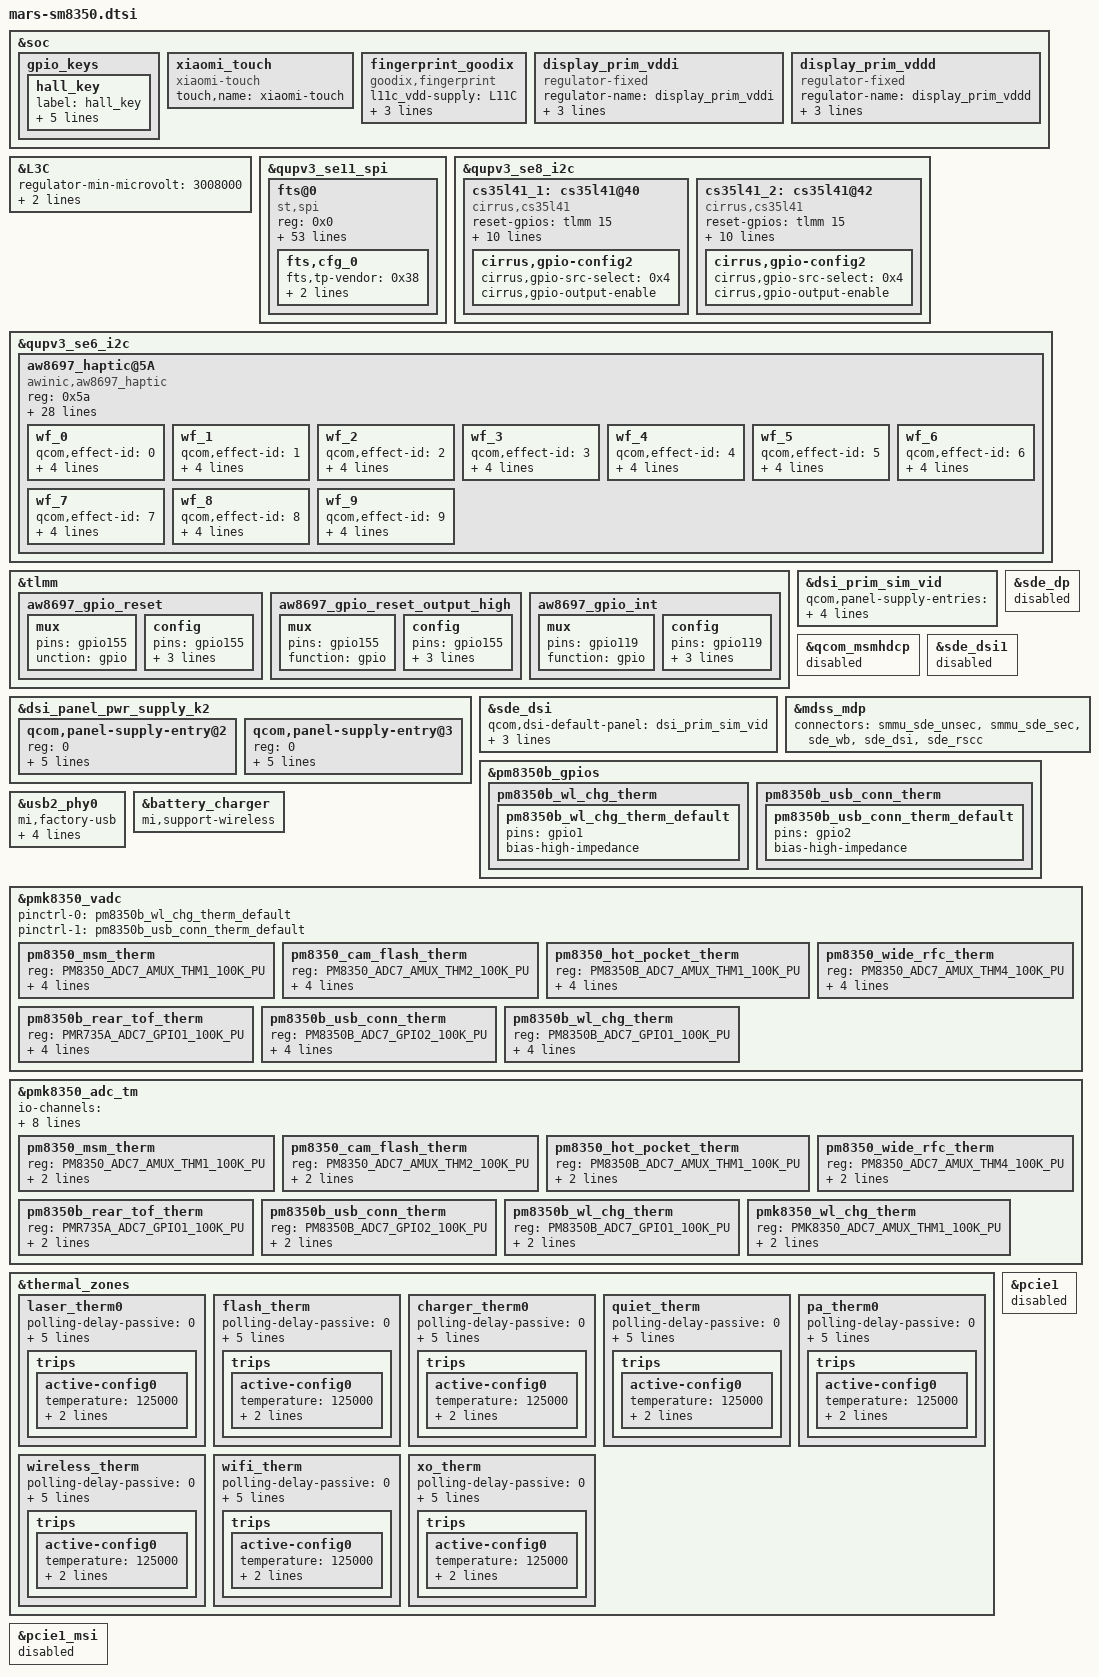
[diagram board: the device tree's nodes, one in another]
/*
this file is for attribution only of mars
And public attribution of xiaomi platforms(like venus and so and)
*/

#include "mars-pinctrl.dtsi"
#include "xiaomi-sm8350-common.dtsi"
#include "mars-audio-overlay.dtsi"
#include "camera/mars-sm8350-camera-sensor.dtsi"

&soc {
	gpio_keys {
		hall_key {
			label = "hall_key";
			gpios = <&tlmm 80 GPIO_ACTIVE_LOW>;
			linux,input-type = <5>;
			linux,code = <0>;
			gpio-key,wakeup;
			debounce-interval = <15>;
		};
	};
	xiaomi_touch {
		compatible = "xiaomi-touch";
		status = "ok";
		touch,name = "xiaomi-touch";
	};

	fingerprint_goodix {
		compatible = "goodix,fingerprint";
		l11c_vdd-supply = <&L11C>;
		goodix,gpio-reset = <&tlmm 39 0x0>;
		goodix,gpio-irq = <&tlmm 38 0x0>;
		fp-gpio-pwr = <&tlmm 13 0x0>;
		status = "ok";
	};

	display_prim_vddi: display_prim_vddi {
		compatible = "regulator-fixed";
		regulator-name = "display_prim_vddi";
		enable-active-high;
		regulator-boot-on;
		gpio = <&tlmm 13 0>;
	};

	display_prim_vddd: display_prim_vddd {
		compatible = "regulator-fixed";
		regulator-name = "display_prim_vddd";
		enable-active-high;
		regulator-boot-on;
		gpio = <&tlmm 74 0>;
	};

};

&L3C {
	regulator-min-microvolt = <3008000>;
	regulator-max-microvolt = <3300000>;
	qcom,init-voltage = <3300000>;
};

&qupv3_se11_spi {
	status = "ok";
	fts@0 {
		status = "ok";
		compatible = "st,spi";
		reg = <0x0>;
		interrupt-parent = <&tlmm>;
		interrupts = <23 0x2008>;
		pinctrl-names = "pmx_ts_active", "pmx_ts_suspend";
		pinctrl-0 = <&mi_ts_active>;
		pinctrl-1 = <&ts_int_suspend &ts_reset_suspend>;
		avdd-supply = <&touch_avddsource_vreg>;
		vdd-supply = <&L2C>;
		fts,pwr-reg-name = "avdd";
		fts,bus-reg-name = "vdd";
		fts,irq-gpio = <&tlmm 23 0x2008>;
		fts,irq-gpio-name = "fts_irq";
		fts,reset-gpio-enable;
		fts,reset-gpio = <&tlmm 22 0x00>;
		fts,reset-gpio-name = "fts_rst";
		fts,irq-flags = <0x2008>;
		fts,x-max = <1440>;
		fts,y-max = <3200>;
		fts,fod-lx = <588>;
		fts,fod-ly = <2358>;
		fts,fod-x-size = <264>;
		fts,fod-y-size = <264>;
		fts,support-fod;
		spi-max-frequency = <7000000>;
		fts,default-fw-name = "st_fts_k2.ftb";
		fts,htp-fw-name = "st_fts_k2_htp.ftb";
		fts,config-array-size = <1>;
		fts,touch-follow-performance-def = <3>;
		fts,touch-tap-sensitivity-def = <4>;
		fts,touch-aim-sensitivity-def = <3>;
		fts,touch-tap-stability-def = <3>;
		fts,cornerfilter-area-step1 = <150>;
		fts,cornerfilter-area-step2 = <280>;
		fts,cornerfilter-area-step3 = <400>;
		fts,touch-deadzone-filter-ver = <2 0 0 0 0 0 0 0
										2 1 0 0 0 0 0 0
										2 2 0 0 0 3199 0 0
										2 3 1439 0 1439 3199 0 0>;
		fts,touch-deadzone-filter-hor = <2 0 0 0 1439 7 0 0
										2 1 0 3192 1439 3199 0 0
										2 2 0 0 0 3199 0 0
										2 3 1439 0 1439 3199 0 0>;
		fts,touch-edgezone-filter-ver = <1 0 0 0 0 0 0 0
										1 1 0 0 0 0 0 0
										1 2 0 0 60 3199 0 0
										1 3 1379 0 1439 3199 0 0>;
		fts,touch-edgezone-filter-hor = <1 0 0 0 1439 70 0 0
										1 1 0 3129 1439 3199 0 0
										1 2 0 0 60 3199 0 0
										1 3 1379 0 1439 3199 0 0>;
		fts,touch-cornerzone-filter-ver = <0 0 0 0 0 0 0 0
										0 1 0 0 0 0 0 0
										0 2 0 2799 250 3199 0 0
										0 3 1189 2799 1439 3199 0 0>;
		fts,touch-cornerzone-filter-hor1 = <0 0 0 0 280 280 0 0
										0 1 0 0 0 0 0 0
										0 2 0 2919 280 3199 0 0
										0 3 0 0 0 0 0 0>;
		fts,touch-cornerzone-filter-hor2 = <0 0 0 0 0 0 0 0
										0 1 1159 0 1439 280 0 0
										0 2 0 0 0 0 0 0
										0 3 1159 2919 1439 3199 0 0>;
		fts,touch-follow-performance = <10 15 1
										8 15 1
										6 15 1
										4 15 1
										2 15 1>;
		fts,touch-tap-sensitivity = <160 150 140 120 100>;
		fts,touch-aim-sensitivity = <10 8 6 4 2>;
		fts,touch-tap-stability = <8 12 15 18 25>;
		fts,touch-expert-array = <6 15 1 120 6 15
								  2 15 1 120 4 15
								  4 15 1 120 2 15>;
		fts,cfg_0 {
			fts,tp-vendor = <0x38>;
			fts,fw-name = "st_fts_k2.ftb";
			fts,limit-name = "stm_fts_production_limits.csv";
		};
	};
};


&qupv3_se8_i2c {
	status = "ok";
	cs35l41_1: cs35l41@40 {
		status = "ok";
		compatible = "cirrus,cs35l41";
		reset-gpios = <&tlmm 15 0>;
		reg = <0x40>;
		interrupt-parent = <&tlmm>;
		interrupts = <44 8>;
		cirrus,temp-warn_threshold = <3>;
		cirrus,boost-peak-milliamp = <4000>;
		cirrus,boost-ind-nanohenry = <1000>;
		cirrus,boost-cap-microfarad = <15>;
		cirrus,asp-sdout-hiz = <3>;
		cirrus,is-mars-pa = <1>;
		sound-name-prefix = "RCV";
		cirrus,gpio-config2 {
			cirrus,gpio-src-select = <0x4>;
			cirrus,gpio-output-enable;
		};
	};
	cs35l41_2: cs35l41@42 {
		compatible = "cirrus,cs35l41";
		reset-gpios = <&tlmm 15 0>;
		reg = <0x42>;
		interrupt-parent = <&tlmm>;
		interrupts = <116 8>;
		cirrus,temp-warn_threshold = <3>;
		cirrus,boost-peak-milliamp = <4000>;
		cirrus,boost-ind-nanohenry = <1000>;
		cirrus,boost-cap-microfarad = <15>;
		cirrus,asp-sdout-hiz = <3>;
		cirrus,is-mars-pa = <1>;
		cirrus,right-channel-amp;
		cirrus,gpio-config2 {
			cirrus,gpio-src-select = <0x4>;
			cirrus,gpio-output-enable;
		};
	};
};

&qupv3_se6_i2c {
	status = "ok";
	aw8697_haptic@5A {
		compatible = "awinic,aw8697_haptic";
		reg = <0x5a>;
		reset-gpio = <&tlmm 155 0>;
		irq-gpio = <&tlmm 119 0>;
		vib_mode = < 0 >;   /*mode:   RAM mode->0; CONT mode -> 1*/
		vib_f0_pre = < 1700 >;
		vib_f0_cali_percen = < 7 >;
		vib_cont_drv_lev = < 73 >;
		vib_cont_drv_lvl_ov = < 73 >;
		vib_cont_td = < 0xf06c >;
		vib_cont_zc_thr = < 0x08f8 >;  /*hq 0x08F8 */
		vib_cont_num_brk = < 3 >;
		vib_f0_coeff = < 260 >; /*Don't modify it    2.604167*/
		vib_f0_trace_parameter = < 9 3 1 31 >;
		vib_bemf_config = < 0 0x08 0x03 0xf8 >;
		vib_sw_brake = < 0x2c >;
		vib_tset = < 0x12 >;
		vib_r_spare = < 0x68 >;
		vib_bstdbg = < 0x30 0xeb 0xd4 0 0 0 >;
		vib_effect_id_boundary = < 10 >;
		vib_effect_max = < 170 >;
		vib_trig_config = < 0 1 0 1 2
						0 1 0 1 2
						0 1 0 1 2 >;
		vib_bst_vol_default = < 0x10 >;
		vib_bst_vol_ram = < 0x10 >;
		vib_bst_vol_rtp = < 0x10 >;
		vib_rtp_time = < 20 20 20 20 20 20 20 20 20000 15000
				 15000 20000 25000 15000 30000 25000 20000 20000 20000 20000
				 20000 20000 20000 20000 20000 20000 20000 20000 20000 20000
				 20000 20000 20000 20000 20000 20000 20000 20000 20000 20000
				 20000 20000 20000 20000 20000 20000 20000 20000 20000 20000
				 20000 20000 20000 20000 20000 20000 20000 20000 20000 20000
				 20000 20000 20000 20000 20000 20000 20000 20000 20000 20000
				 20000 20000 20000 20000 20000 20000 20000 20000 20000 20000
				 20000 20000 20000 20000 20000 20000 20000 20000 20000 20000
				 20000 20000 20000 20000 20000 20000 20000 20000 20000 20000
				 20000 20000 20000 20000 20000 20000 20000 20000 20000 20000
				 20000 20000 20000 20000 20000 20000 20000 20000 20000 20000
				 20000 20000 20000 20000 20000 20000 20000 20000 20000 20000
				 20000 20000 20000 20000 20000 20000 20000 20000 20000 20000
				 20000 20000 20000 20000 20000 20000 20000 20000 20000 20000
				 20000 20000 20000 20000 20000 20000 20000 20000 20000 20000
				 20000 20000 20000 20000 20000 20000 20000 20000 20000 20000
				 20000 20000 20000 20000 20000 >;
		pinctrl-names = "aw8697_reset_reset","aw8697_reset_active","aw8697_interrupt_active";
		pinctrl-0 = <&aw8697_gpio_reset>;
		pinctrl-1 = <&aw8697_gpio_reset_output_high>;
		pinctrl-2 = <&aw8697_gpio_int>;
		status = "ok";
		wf_0 {
			/*CLICK*/
			qcom,effect-id = <0>;
			qcom,wf-vmax-mv = <3600>;
			qcom,wf-pattern = [3e 3e];
			qcom,wf-brake-pattern = [02 01 00 00];
			qcom,wf-play-rate-us = <20000>;
		};
		wf_1 {
			/*DOUBLE CLICK*/
			qcom,effect-id = <1>;
			qcom,wf-vmax-mv = <3600>;
			qcom,wf-pattern = [7e 3e];
			qcom,wf-brake-pattern = [03 01 00 00];
			qcom,wf-play-rate-us = <20000>;
		};
		wf_2 {
			/*TICK*/
			qcom,effect-id = <2>;
			qcom,wf-vmax-mv = <3600>;
			qcom,wf-pattern = [7e 3e];
			qcom,wf-brake-pattern = [02 01 00 00];
			qcom,wf-play-rate-us = <20000>;
		};
		wf_3 {
			/*THUD*/
			qcom,effect-id = <3>;
			qcom,wf-vmax-mv = <3600>;
			qcom,wf-pattern = [3e 3e];
			qcom,wf-brake-pattern = [02 01 00 00];
			qcom,wf-play-rate-us = <20000>;
		};
		wf_4 {
			/*POP*/
			qcom,effect-id = <4>;
			qcom,wf-vmax-mv = <3600>;
			qcom,wf-pattern = [3e 3e];
			qcom,wf-brake-pattern = [02 01 00 00];
			qcom,wf-play-rate-us = <28000>;
		};
		wf_5 {
			/*HEAVY CLICK*/
			qcom,effect-id = <5>;
			qcom,wf-vmax-mv = <3600>;
			qcom,wf-pattern = [7e 7e 7e];
			qcom,wf-brake-pattern = [03 03 01 00];
			qcom,wf-play-rate-us = <20000>;
		};
		wf_6 {
			/*id 6*/
			qcom,effect-id = <6>;
			qcom,wf-vmax-mv = <3600>;
			qcom,wf-pattern = [3e 3e];
			qcom,wf-brake-pattern = [02 01 00 00];
			qcom,wf-play-rate-us = <20000>;
		};
		wf_7 {
			/*id 7*/
			qcom,effect-id = <7>;
			qcom,wf-vmax-mv = <3600>;
			qcom,wf-pattern = [3e 3e];
			qcom,wf-brake-pattern = [02 01 00 00];
			qcom,wf-play-rate-us = <20000>;
		};
		wf_8 {
			/*id 8*/
			qcom,effect-id = <8>;
			qcom,wf-vmax-mv = <3600>;
			qcom,wf-pattern = [3e 3e];
			qcom,wf-brake-pattern = [02 01 00 00];
			qcom,wf-play-rate-us = <20000>;
		};
		wf_9 {
			/*id 9*/
			qcom,effect-id = <9>;
			qcom,wf-vmax-mv = <3600>;
			qcom,wf-pattern = [3e 3e];
			qcom,wf-brake-pattern = [02 01 00 00];
			qcom,wf-play-rate-us = <20000>;
		};
	};
};

&tlmm {
	/* AW8697_RESET_N */
	aw8697_gpio_reset: aw8697_gpio_reset {
		mux {
			pins = "gpio155";
			unction = "gpio";
		};

		config {
			pins = "gpio155";
			drive-strength = <2>;
			bias-disable;
			output-low;
		};
	};
	/* AW8697_RESET_N, state device active*/
	aw8697_gpio_reset_output_high: aw8697_gpio_reset_output_high {
		mux {
			pins = "gpio155";
			function = "gpio";
		};

		config {
			pins = "gpio155";
			drive-strength = <2>;
			bias-disable;
			output-high;
		};
	};
	/* AW8697_INTERRUPT_N */
	aw8697_gpio_int: aw8697_gpio_int {
		mux {
			pins = "gpio119";
			function = "gpio";
		};

		config {
			pins = "gpio119";
			drive-strength = <2>;
			bias-pull-up;
			input-enable;
		};
	};
};

&dsi_prim_sim_vid {
	qcom,panel-supply-entries = <&dsi_panel_pwr_supply_k2>;
	qcom,mdss-dsi-bl-pmic-control-type = "bl_ctrl_dcs";
	qcom,platform-reset-gpio = <&tlmm 24 0>;
};

&dsi_panel_pwr_supply_k2 {
	qcom,panel-supply-entry@2 {
		reg = <0>;
		qcom,supply-name = "avdd";
		qcom,supply-min-voltage = <1800000>;
		qcom,supply-max-voltage = <1800000>;
		qcom,supply-enable-load = <60700>;
		qcom,supply-disable-load = <80>;
	};

	qcom,panel-supply-entry@3 {
		reg = <0>;
		qcom,supply-name = "vddd";
		qcom,supply-min-voltage = <1800000>;
		qcom,supply-max-voltage = <1800000>;
		qcom,supply-enable-load = <60700>;
		qcom,supply-disable-load = <80>;
	};
};

&sde_dsi {
	qcom,dsi-default-panel = <&dsi_prim_sim_vid>;
	vddio-supply = <&display_prim_vddi>;
	avdd-supply = <&L12C>;
	vddd-supply = <&display_prim_vddd>;
};

&sde_dp {
	status = "disabled";
};

&qcom_msmhdcp {
	status = "disabled";
};

&sde_dsi1 {
	status = "disabled";
};

&mdss_mdp {
	connectors = <&smmu_sde_unsec &smmu_sde_sec &sde_wb &sde_dsi
		&sde_rscc>;
};

&pm8350b_gpios {
	pm8350b_wl_chg_therm {
		pm8350b_wl_chg_therm_default: pm8350b_wl_chg_therm_default {
			pins = "gpio1";
			bias-high-impedance;
		};
	};

	pm8350b_usb_conn_therm {
		pm8350b_usb_conn_therm_default: pm8350b_usb_conn_therm_default {
			pins = "gpio2";
			bias-high-impedance;
		};
	};
};

&usb2_phy0 {
	mi,factory-usb;
	qcom,param-override-seq-fac =
	<0xa5 0x6c	/* override_x0 */
	 0x0e 0x70	/* override_x1 */
	 0x04 0x74>;	/* override x2 */
	qcom,param-override-seq =
	<0x27 0x6c	/* override_x0 */
	 0x0b 0x70	/* override_x1 */
	 0x08 0x74>;	/* override x2 */
};

&battery_charger {
	mi,support-wireless;
};

&pmk8350_vadc {
	pinctrl-names = "default";
	pinctrl-0 = <&pm8350b_wl_chg_therm_default>;
	pinctrl-1 = <&pm8350b_usb_conn_therm_default>;

	pm8350_msm_therm {
		reg = <PM8350_ADC7_AMUX_THM1_100K_PU>;
		label = "pm8350_msm_therm";
		qcom,ratiometric;
		qcom,hw-settle-time = <200>;
		qcom,pre-scaling = <1 1>;
	};

	pm8350_cam_flash_therm {
		reg = <PM8350_ADC7_AMUX_THM2_100K_PU>;
		label = "pm8350_cam_flash_therm";
		qcom,ratiometric;
		qcom,hw-settle-time = <200>;
		qcom,pre-scaling = <1 1>;
	};

	pm8350_hot_pocket_therm {
		reg = <PM8350B_ADC7_AMUX_THM1_100K_PU>;
		label = "pm8350_hot_pocket_therm";
		qcom,ratiometric;
		qcom,hw-settle-time = <200>;
		qcom,pre-scaling = <1 1>;
	};

	pm8350_wide_rfc_therm {
		reg = <PM8350_ADC7_AMUX_THM4_100K_PU>;
		label = "pm8350_wide_rfc_therm";
		qcom,ratiometric;
		qcom,hw-settle-time = <200>;
		qcom,pre-scaling = <1 1>;
	};

	pm8350b_rear_tof_therm {
		reg = <PMR735A_ADC7_GPIO1_100K_PU>;
		label = "pm8350b_rear_tof_therm";
		qcom,ratiometric;
		qcom,hw-settle-time = <200>;
		qcom,pre-scaling = <1 1>;
	};

	pm8350b_usb_conn_therm {
		reg = <PM8350B_ADC7_GPIO2_100K_PU>;
		label = "pm8350b_usb_conn_therm";
		qcom,ratiometric;
		qcom,hw-settle-time = <200>;
		qcom,pre-scaling = <1 1>;
	};

	pm8350b_wl_chg_therm {
		reg = <PM8350B_ADC7_GPIO1_100K_PU>;
		label = "pm8350b_wl_chg_therm";
		qcom,ratiometric;
		qcom,hw-settle-time = <200>;
		qcom,pre-scaling = <1 1>;
	};
};

&pmk8350_adc_tm {
	io-channels = <&pmk8350_vadc PM8350_ADC7_AMUX_THM1_100K_PU>,
			<&pmk8350_vadc PM8350_ADC7_AMUX_THM2_100K_PU>,
			<&pmk8350_vadc PM8350B_ADC7_AMUX_THM1_100K_PU>,
			<&pmk8350_vadc PM8350_ADC7_AMUX_THM4_100K_PU>,
			<&pmk8350_vadc PMR735A_ADC7_GPIO1_100K_PU>,
			<&pmk8350_vadc PM8350B_ADC7_GPIO2_100K_PU>,
			<&pmk8350_vadc PM8350B_ADC7_GPIO1_100K_PU>,
			<&pmk8350_vadc PMK8350_ADC7_AMUX_THM1_100K_PU>;

	pm8350_msm_therm {
		reg = <PM8350_ADC7_AMUX_THM1_100K_PU>;
		qcom,ratiometric;
		qcom,hw-settle-time = <200>;
	};

	pm8350_cam_flash_therm {
		reg = <PM8350_ADC7_AMUX_THM2_100K_PU>;
		qcom,ratiometric;
		qcom,hw-settle-time = <200>;
	};

	pm8350_hot_pocket_therm {
		reg = <PM8350B_ADC7_AMUX_THM1_100K_PU>;
		qcom,ratiometric;
		qcom,hw-settle-time = <200>;
	};

	pm8350_wide_rfc_therm {
		reg = <PM8350_ADC7_AMUX_THM4_100K_PU>;
		qcom,ratiometric;
		qcom,hw-settle-time = <200>;
	};

	pm8350b_rear_tof_therm {
		reg = <PMR735A_ADC7_GPIO1_100K_PU>;
		qcom,ratiometric;
		qcom,hw-settle-time = <200>;
	};

	pm8350b_usb_conn_therm {
		reg = <PM8350B_ADC7_GPIO2_100K_PU>;
		qcom,ratiometric;
		qcom,hw-settle-time = <200>;
	};

	pm8350b_wl_chg_therm {
		reg = <PM8350B_ADC7_GPIO1_100K_PU>;
		qcom,ratiometric;
		qcom,hw-settle-time = <200>;
	};

	pmk8350_wl_chg_therm {
		reg = <PMK8350_ADC7_AMUX_THM1_100K_PU>;
		qcom,ratiometric;
		qcom,hw-settle-time = <200>;
	};
};

&thermal_zones {
	laser_therm0 {
		polling-delay-passive = <0>;
		polling-delay = <0>;
		thermal-governor = "user_space";
		thermal-sensors = <&pmk8350_adc_tm PM8350_ADC7_AMUX_THM1_100K_PU>;
		wake-capable-sensor;
		trips {
			active-config0 {
				temperature = <125000>;
				hysteresis = <1000>;
				type = "passive";
			};
		};
	};

	flash_therm {
		polling-delay-passive = <0>;
		polling-delay = <0>;
		thermal-governor = "user_space";
		thermal-sensors = <&pmk8350_adc_tm PM8350_ADC7_AMUX_THM2_100K_PU>;
		wake-capable-sensor;
		trips {
			active-config0 {
				temperature = <125000>;
				hysteresis = <1000>;
				type = "passive";
			};
		};
	};

	charger_therm0 {
		polling-delay-passive = <0>;
		polling-delay = <0>;
		thermal-governor = "user_space";
		thermal-sensors = <&pmk8350_adc_tm PM8350B_ADC7_AMUX_THM1_100K_PU>;
		wake-capable-sensor;
		trips {
			active-config0 {
				temperature = <125000>;
				hysteresis = <1000>;
				type = "passive";
			};
		};
	};

	quiet_therm {
		polling-delay-passive = <0>;
		polling-delay = <0>;
		thermal-governor = "user_space";
		thermal-sensors = <&pmk8350_adc_tm PM8350_ADC7_AMUX_THM4_100K_PU>;
		wake-capable-sensor;
		trips {
			active-config0 {
				temperature = <125000>;
				hysteresis = <1000>;
				type = "passive";
			};
		};
	};

	pa_therm0 {
		polling-delay-passive = <0>;
		polling-delay = <0>;
		thermal-governor = "user_space";
		thermal-sensors = <&pmk8350_adc_tm PMR735A_ADC7_GPIO1_100K_PU>;
		wake-capable-sensor;
		trips {
			active-config0 {
				temperature = <125000>;
				hysteresis = <1000>;
				type = "passive";
			};
		};
	};

	wireless_therm {
		polling-delay-passive = <0>;
		polling-delay = <0>;
		thermal-governor = "user_space";
		thermal-sensors = <&pmk8350_adc_tm PM8350B_ADC7_GPIO2_100K_PU>;
		wake-capable-sensor;
		trips {
			active-config0 {
				temperature = <125000>;
				hysteresis = <1000>;
				type = "passive";
			};
		};
	};

	wifi_therm {
		polling-delay-passive = <0>;
		polling-delay = <0>;
		thermal-governor = "user_space";
		thermal-sensors = <&pmk8350_adc_tm PM8350B_ADC7_GPIO1_100K_PU>;
		wake-capable-sensor;
		trips {
			active-config0 {
				temperature = <125000>;
				hysteresis = <1000>;
				type = "passive";
			};
		};
	};

	xo_therm {
		polling-delay-passive = <0>;
		polling-delay = <0>;
		thermal-governor = "user_space";
		thermal-sensors = <&pmk8350_adc_tm PMK8350_ADC7_AMUX_THM1_100K_PU>;
		wake-capable-sensor;
		trips {
			active-config0 {
				temperature = <125000>;
				hysteresis = <1000>;
				type = "passive";
			};
		};
	};
};

&pcie1 {
	status = "disabled";
};

&pcie1_msi {
	status = "disabled";
};
